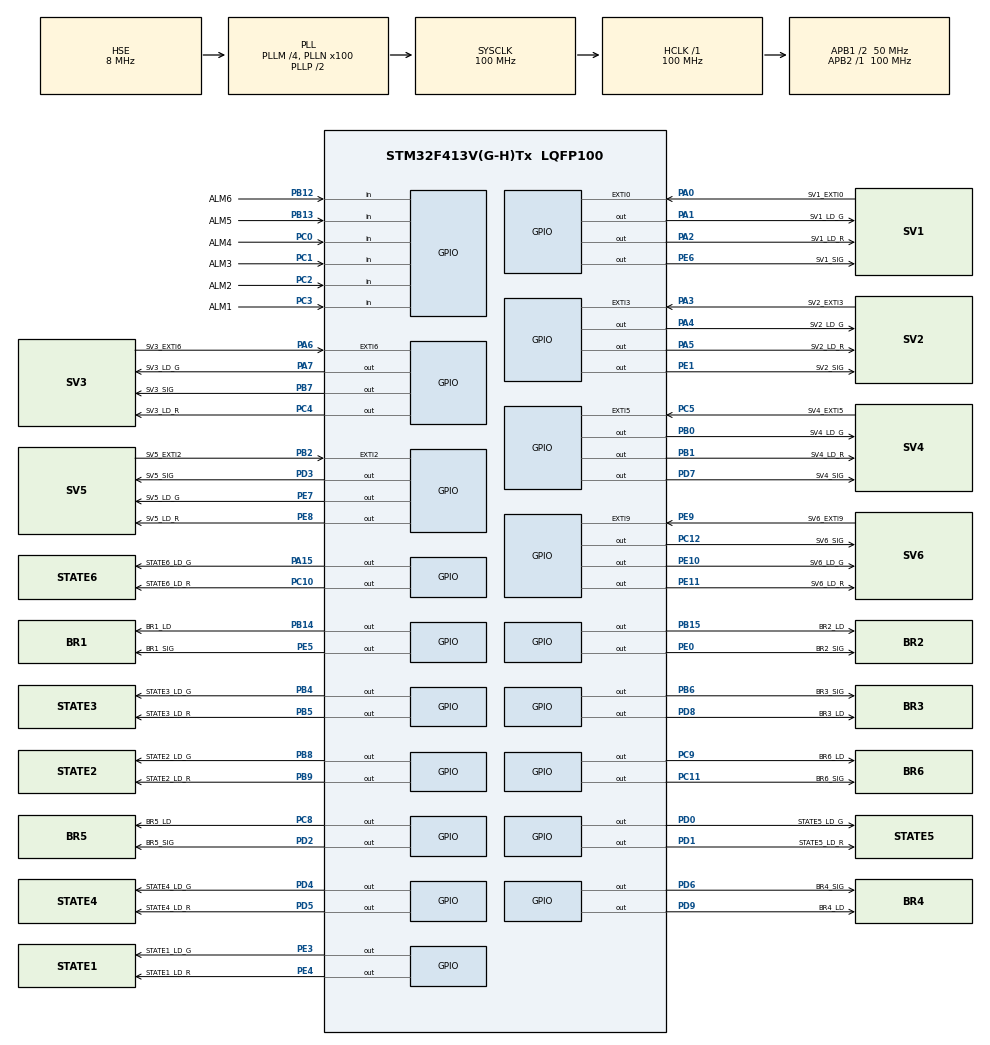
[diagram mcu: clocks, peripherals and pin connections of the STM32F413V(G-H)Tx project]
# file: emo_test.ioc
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Mcu.Family=STM32F4
Mcu.Name=STM32F413V(G-H)Tx
Mcu.Package=LQFP100
NVIC.EXTI0_IRQn=true\:0\:0\:false\:false\:true\:true\:true\:true
NVIC.EXTI2_IRQn=true\:0\:0\:false\:false\:true\:true\:true\:true
NVIC.EXTI3_IRQn=true\:0\:0\:false\:false\:true\:true\:true\:true
NVIC.EXTI9_5_IRQn=true\:0\:0\:false\:false\:true\:true\:true\:true
NVIC.PriorityGroup=NVIC_PRIORITYGROUP_4
NVIC.TIM2_IRQn=true\:0\:0\:false\:false\:true\:true\:true\:true
PA0.GPIO_Label=SV1_EXTI0
PA0.Signal=GPXTI0
PA1.GPIO_Label=SV1_LD_G
PA1.Signal=GPIO_Output
PA13.Mode=Trace_Asynchronous_SW
PA13.Signal=SYS_JTMS-SWDIO
PA14.Mode=Trace_Asynchronous_SW
PA14.Signal=SYS_JTCK-SWCLK
PA15.GPIO_Label=STATE6_LD_G
PA15.Signal=GPIO_Output
PA2.GPIO_Label=SV1_LD_R
PA2.Signal=GPIO_Output
PA3.GPIO_Label=SV2_EXTI3
PA3.Signal=GPXTI3
PA4.GPIO_Label=SV2_LD_G
PA4.Signal=GPIO_Output
PA5.GPIO_Label=SV2_LD_R
PA5.Signal=GPIO_Output
PA6.GPIO_Label=SV3_EXTI6
PA6.Signal=GPXTI6
PA7.GPIO_Label=SV3_LD_G
PA7.Signal=GPIO_Output
PB0.GPIO_Label=SV4_LD_G
PB0.Signal=GPIO_Output
PB1.GPIO_Label=SV4_LD_R
PB1.Signal=GPIO_Output
PB12.GPIO_Label=ALM6
PB12.Signal=GPIO_Input
PB13.GPIO_Label=ALM5
PB13.Signal=GPIO_Input
PB14.GPIO_Label=BR1_LD
PB14.Signal=GPIO_Output
PB15.GPIO_Label=BR2_LD
PB15.Signal=GPIO_Output
PB2.GPIO_Label=SV5_EXTI2
PB2.Signal=GPXTI2
PB3.Mode=Trace_Asynchronous_SW
PB3.Signal=SYS_JTDO-SWO
PB4.GPIO_Label=STATE3_LD_G
PB4.Signal=GPIO_Output
PB5.GPIO_Label=STATE3_LD_R
PB5.Signal=GPIO_Output
PB6.GPIO_Label=BR3_SIG
PB6.Signal=GPIO_Output
PB7.GPIO_Label=SV3_SIG
PB7.Signal=GPIO_Output
PB8.GPIO_Label=STATE2_LD_G
PB8.Signal=GPIO_Output
PB9.GPIO_Label=STATE2_LD_R
PB9.Signal=GPIO_Output
PC0.GPIO_Label=ALM4
PC0.Signal=GPIO_Input
PC1.GPIO_Label=ALM3
PC1.Signal=GPIO_Input
PC10.GPIO_Label=STATE6_LD_R
PC10.Signal=GPIO_Output
PC11.GPIO_Label=BR6_SIG
PC11.Signal=GPIO_Output
PC12.GPIO_Label=SV6_SIG
PC12.Signal=GPIO_Output
PC2.GPIO_Label=ALM2
PC2.Signal=GPIO_Input
PC3.GPIO_Label=ALM1
PC3.Signal=GPIO_Input
PC4.GPIO_Label=SV3_LD_R
PC4.Signal=GPIO_Output
PC5.GPIO_Label=SV4_EXTI5
PC5.Signal=GPXTI5
PC8.GPIO_Label=BR5_LD
PC8.Signal=GPIO_Output
PC9.GPIO_Label=BR6_LD
PC9.Signal=GPIO_Output
PD0.GPIO_Label=STATE5_LD_G
PD0.Signal=GPIO_Output
PD1.GPIO_Label=STATE5_LD_R
PD1.Signal=GPIO_Output
PD2.GPIO_Label=BR5_SIG
PD2.Signal=GPIO_Output
PD3.GPIO_Label=SV5_SIG
PD3.Signal=GPIO_Output
PD4.GPIO_Label=STATE4_LD_G
PD4.Signal=GPIO_Output
PD5.GPIO_Label=STATE4_LD_R
PD5.Signal=GPIO_Output
PD6.GPIO_Label=BR4_SIG
PD6.Signal=GPIO_Output
PD7.GPIO_Label=SV4_SIG
PD7.Signal=GPIO_Output
PD8.GPIO_Label=BR3_LD
PD8.Signal=GPIO_Output
PD9.GPIO_Label=BR4_LD
PD9.Signal=GPIO_Output
PE0.GPIO_Label=BR2_SIG
PE0.Signal=GPIO_Output
PE1.GPIO_Label=SV2_SIG
PE1.Signal=GPIO_Output
PE10.GPIO_Label=SV6_LD_G
PE10.Signal=GPIO_Output
PE11.GPIO_Label=SV6_LD_R
PE11.Signal=GPIO_Output
PE3.GPIO_Label=STATE1_LD_G
PE3.Signal=GPIO_Output
PE4.GPIO_Label=STATE1_LD_R
PE4.Signal=GPIO_Output
PE5.GPIO_Label=BR1_SIG
PE5.Signal=GPIO_Output
PE6.GPIO_Label=SV1_SIG
PE6.Signal=GPIO_Output
PE7.GPIO_Label=SV5_LD_G
PE7.Signal=GPIO_Output
PE8.GPIO_Label=SV5_LD_R
PE8.Signal=GPIO_Output
PE9.GPIO_Label=SV6_EXTI9
PE9.Signal=GPXTI9
PH0\ -\ OSC_IN.Mode=HSE-External-Clock-Source
PH0\ -\ OSC_IN.Signal=RCC_OSC_IN
PH1\ -\ OSC_OUT.Mode=HSE-External-Clock-Source
PH1\ -\ OSC_OUT.Signal=RCC_OSC_OUT
ProjectManager.HeapSize=0x200
ProjectManager.StackSize=0x400
ProjectManager.TargetToolchain=STM32CubeIDE
RCC.AHBFreq_Value=100000000
RCC.APB1CLKDivider=RCC_HCLK_DIV2
RCC.APB1Freq_Value=50000000
RCC.APB1TimFreq_Value=100000000
RCC.APB2Freq_Value=100000000
RCC.APB2TimFreq_Value=100000000
RCC.CortexFreq_Value=100000000
RCC.HCLKFreq_Value=100000000
RCC.HSE_VALUE=8000000
RCC.PLLM=4
RCC.PLLN=100
RCC.PLLSourceVirtual=RCC_PLLSOURCE_HSE
RCC.SYSCLKFreq_VALUE=100000000
RCC.SYSCLKSource=RCC_SYSCLKSOURCE_PLLCLK
RCC.USBFreq_Value=100000000
RCC.VCOOutputFreq_Value=200000000
TIM2.Period=100
TIM2.Prescaler=16-1
VP_TIM2_VS_ClockSourceINT.Mode=Internal
board=custom

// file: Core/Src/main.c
/* USER CODE BEGIN Header */
/**
  ******************************************************************************
  * @file           : main.c
  * @brief          : Main program body
  ******************************************************************************
  * @attention
  *
  * Copyright (c) 2024 STMicroelectronics.
  * All rights reserved.
  *
  * This software is licensed under terms that can be found in the LICENSE file
  * in the root directory of this software component.
  * If no LICENSE file comes with this software, it is provided AS-IS.
  *
  ******************************************************************************
  */
/* USER CODE END Header */
#include "main.h"

/* USER CODE BEGIN Includes */
#include "main_cpp.h"
/* USER CODE END Includes */

TIM_HandleTypeDef htim2;

void SystemClock_Config(void);
static void MX_GPIO_Init(void);
static void MX_TIM2_Init(void);

int main(void)
{

  /* MCU Configuration--------------------------------------------------------*/

  /* Reset of all peripherals, Initializes the Flash interface and the Systick. */
  HAL_Init();

  /* Configure the system clock */
  SystemClock_Config();

  /* Initialize all configured peripherals */
  MX_GPIO_Init();
  MX_TIM2_Init();
  /* USER CODE BEGIN 2 */

  main_cpp();
  /* USER CODE END 2 */

  /* Infinite loop */
  while (1)
  {

  }
}

void SystemClock_Config(void)
{
  RCC_OscInitTypeDef RCC_OscInitStruct = {0};
  RCC_ClkInitTypeDef RCC_ClkInitStruct = {0};

  /** Configure the main internal regulator output voltage
  */
  __HAL_RCC_PWR_CLK_ENABLE();
  __HAL_PWR_VOLTAGESCALING_CONFIG(PWR_REGULATOR_VOLTAGE_SCALE1);

  /** Initializes the RCC Oscillators according to the specified parameters
  * in the RCC_OscInitTypeDef structure.
  */
  RCC_OscInitStruct.OscillatorType = RCC_OSCILLATORTYPE_HSE;
  RCC_OscInitStruct.HSEState = RCC_HSE_BYPASS;
  RCC_OscInitStruct.PLL.PLLState = RCC_PLL_ON;
  RCC_OscInitStruct.PLL.PLLSource = RCC_PLLSOURCE_HSE;
  RCC_OscInitStruct.PLL.PLLM = 4;
  RCC_OscInitStruct.PLL.PLLN = 100;
  RCC_OscInitStruct.PLL.PLLP = RCC_PLLP_DIV2;
  RCC_OscInitStruct.PLL.PLLQ = 2;
  RCC_OscInitStruct.PLL.PLLR = 2;
  if (HAL_RCC_OscConfig(&RCC_OscInitStruct) != HAL_OK)
  {
    Error_Handler();
  }

  /** Initializes the CPU, AHB and APB buses clocks
  */
  RCC_ClkInitStruct.ClockType = RCC_CLOCKTYPE_HCLK|RCC_CLOCKTYPE_SYSCLK
                              |RCC_CLOCKTYPE_PCLK1|RCC_CLOCKTYPE_PCLK2;
  RCC_ClkInitStruct.SYSCLKSource = RCC_SYSCLKSOURCE_PLLCLK;
  RCC_ClkInitStruct.AHBCLKDivider = RCC_SYSCLK_DIV1;
  RCC_ClkInitStruct.APB1CLKDivider = RCC_HCLK_DIV2;
  RCC_ClkInitStruct.APB2CLKDivider = RCC_HCLK_DIV1;

  if (HAL_RCC_ClockConfig(&RCC_ClkInitStruct, FLASH_LATENCY_3) != HAL_OK)
  {
    Error_Handler();
  }
}

static void MX_TIM2_Init(void)
{

  TIM_ClockConfigTypeDef sClockSourceConfig = {0};
  TIM_MasterConfigTypeDef sMasterConfig = {0};

  htim2.Instance = TIM2;
  htim2.Init.Prescaler = 16-1;
  htim2.Init.CounterMode = TIM_COUNTERMODE_UP;
  htim2.Init.Period = 100;
  htim2.Init.ClockDivision = TIM_CLOCKDIVISION_DIV1;
  htim2.Init.AutoReloadPreload = TIM_AUTORELOAD_PRELOAD_DISABLE;
  if (HAL_TIM_Base_Init(&htim2) != HAL_OK)
  {
    Error_Handler();
  }
  sClockSourceConfig.ClockSource = TIM_CLOCKSOURCE_INTERNAL;
  if (HAL_TIM_ConfigClockSource(&htim2, &sClockSourceConfig) != HAL_OK)
  {
    Error_Handler();
  }
  sMasterConfig.MasterOutputTrigger = TIM_TRGO_RESET;
  sMasterConfig.MasterSlaveMode = TIM_MASTERSLAVEMODE_DISABLE;
  if (HAL_TIMEx_MasterConfigSynchronization(&htim2, &sMasterConfig) != HAL_OK)
  {
    Error_Handler();
  }

}

static void MX_GPIO_Init(void)
{
  GPIO_InitTypeDef GPIO_InitStruct = {0};

  /* GPIO Ports Clock Enable */
  __HAL_RCC_GPIOE_CLK_ENABLE();
  __HAL_RCC_GPIOH_CLK_ENABLE();
  __HAL_RCC_GPIOC_CLK_ENABLE();
  __HAL_RCC_GPIOA_CLK_ENABLE();
  __HAL_RCC_GPIOB_CLK_ENABLE();
  __HAL_RCC_GPIOD_CLK_ENABLE();

  /*Configure GPIO pin Output Level */
  HAL_GPIO_WritePin(GPIOE, STATE1_LD_G_Pin|STATE1_LD_R_Pin|BR1_SIG_Pin|SV1_SIG_Pin
                          |SV5_LD_G_Pin|SV5_LD_R_Pin|SV6_LD_G_Pin|SV6_LD_R_Pin
                          |BR2_SIG_Pin|SV2_SIG_Pin, GPIO_PIN_RESET);

  /*Configure GPIO pin Output Level */
  HAL_GPIO_WritePin(GPIOA, SV1_LD_G_Pin|SV1_LD_R_Pin|SV2_LD_G_Pin|SV2_LD_R_Pin
                          |SV3_LD_G_Pin|STATE6_LD_G_Pin, GPIO_PIN_RESET);

  /*Configure GPIO pin Output Level */
  HAL_GPIO_WritePin(GPIOC, SV3_LD_R_Pin|BR5_LD_Pin|BR6_LD_Pin|STATE6_LD_R_Pin
                          |BR6_SIG_Pin|SV6_SIG_Pin, GPIO_PIN_RESET);

  /*Configure GPIO pin Output Level */
  HAL_GPIO_WritePin(GPIOB, SV4_LD_G_Pin|SV4_LD_R_Pin|BR1_LD_Pin|BR2_LD_Pin
                          |STATE3_LD_G_Pin|STATE3_LD_R_Pin|BR3_SIG_Pin|SV3_SIG_Pin
                          |STATE2_LD_G_Pin|STATE2_LD_R_Pin, GPIO_PIN_RESET);

  /*Configure GPIO pin Output Level */
  HAL_GPIO_WritePin(GPIOD, BR3_LD_Pin|BR4_LD_Pin|STATE5_LD_G_Pin|STATE5_LD_R_Pin
                          |BR5_SIG_Pin|SV5_SIG_Pin|STATE4_LD_G_Pin|STATE4_LD_R_Pin
                          |BR4_SIG_Pin|SV4_SIG_Pin, GPIO_PIN_RESET);

  /*Configure GPIO pins : STATE1_LD_G_Pin STATE1_LD_R_Pin BR1_SIG_Pin SV1_SIG_Pin
                           SV5_LD_G_Pin SV5_LD_R_Pin SV6_LD_G_Pin SV6_LD_R_Pin
                           BR2_SIG_Pin SV2_SIG_Pin */
  GPIO_InitStruct.Pin = STATE1_LD_G_Pin|STATE1_LD_R_Pin|BR1_SIG_Pin|SV1_SIG_Pin
                          |SV5_LD_G_Pin|SV5_LD_R_Pin|SV6_LD_G_Pin|SV6_LD_R_Pin
                          |BR2_SIG_Pin|SV2_SIG_Pin;
  GPIO_InitStruct.Mode = GPIO_MODE_OUTPUT_PP;
  GPIO_InitStruct.Pull = GPIO_NOPULL;
  GPIO_InitStruct.Speed = GPIO_SPEED_FREQ_LOW;
  HAL_GPIO_Init(GPIOE, &GPIO_InitStruct);

  /*Configure GPIO pins : ALM4_Pin ALM3_Pin ALM2_Pin ALM1_Pin */
  GPIO_InitStruct.Pin = ALM4_Pin|ALM3_Pin|ALM2_Pin|ALM1_Pin;
  GPIO_InitStruct.Mode = GPIO_MODE_INPUT;
  GPIO_InitStruct.Pull = GPIO_NOPULL;
  HAL_GPIO_Init(GPIOC, &GPIO_InitStruct);

  /*Configure GPIO pins : SV1_EXTI0_Pin SV2_EXTI3_Pin SV3_EXTI6_Pin */
  GPIO_InitStruct.Pin = SV1_EXTI0_Pin|SV2_EXTI3_Pin|SV3_EXTI6_Pin;
  GPIO_InitStruct.Mode = GPIO_MODE_IT_RISING;
  GPIO_InitStruct.Pull = GPIO_NOPULL;
  HAL_GPIO_Init(GPIOA, &GPIO_InitStruct);

  /*Configure GPIO pins : SV1_LD_G_Pin SV1_LD_R_Pin SV2_LD_G_Pin SV2_LD_R_Pin
                           SV3_LD_G_Pin STATE6_LD_G_Pin */
  GPIO_InitStruct.Pin = SV1_LD_G_Pin|SV1_LD_R_Pin|SV2_LD_G_Pin|SV2_LD_R_Pin
                          |SV3_LD_G_Pin|STATE6_LD_G_Pin;
  GPIO_InitStruct.Mode = GPIO_MODE_OUTPUT_PP;
  GPIO_InitStruct.Pull = GPIO_NOPULL;
  GPIO_InitStruct.Speed = GPIO_SPEED_FREQ_LOW;
  HAL_GPIO_Init(GPIOA, &GPIO_InitStruct);

  /*Configure GPIO pins : SV3_LD_R_Pin BR5_LD_Pin BR6_LD_Pin STATE6_LD_R_Pin
                           BR6_SIG_Pin SV6_SIG_Pin */
  GPIO_InitStruct.Pin = SV3_LD_R_Pin|BR5_LD_Pin|BR6_LD_Pin|STATE6_LD_R_Pin
                          |BR6_SIG_Pin|SV6_SIG_Pin;
  GPIO_InitStruct.Mode = GPIO_MODE_OUTPUT_PP;
  GPIO_InitStruct.Pull = GPIO_NOPULL;
  GPIO_InitStruct.Speed = GPIO_SPEED_FREQ_LOW;
  HAL_GPIO_Init(GPIOC, &GPIO_InitStruct);

  /*Configure GPIO pin : SV4_EXTI5_Pin */
  GPIO_InitStruct.Pin = SV4_EXTI5_Pin;
  GPIO_InitStruct.Mode = GPIO_MODE_IT_RISING;
  GPIO_InitStruct.Pull = GPIO_NOPULL;
  HAL_GPIO_Init(SV4_EXTI5_GPIO_Port, &GPIO_InitStruct);

  /*Configure GPIO pins : SV4_LD_G_Pin SV4_LD_R_Pin BR1_LD_Pin BR2_LD_Pin
                           STATE3_LD_G_Pin STATE3_LD_R_Pin BR3_SIG_Pin SV3_SIG_Pin
                           STATE2_LD_G_Pin STATE2_LD_R_Pin */
  GPIO_InitStruct.Pin = SV4_LD_G_Pin|SV4_LD_R_Pin|BR1_LD_Pin|BR2_LD_Pin
                          |STATE3_LD_G_Pin|STATE3_LD_R_Pin|BR3_SIG_Pin|SV3_SIG_Pin
                          |STATE2_LD_G_Pin|STATE2_LD_R_Pin;
  GPIO_InitStruct.Mode = GPIO_MODE_OUTPUT_PP;
  GPIO_InitStruct.Pull = GPIO_NOPULL;
  GPIO_InitStruct.Speed = GPIO_SPEED_FREQ_LOW;
  HAL_GPIO_Init(GPIOB, &GPIO_InitStruct);

  /*Configure GPIO pin : SV5_EXTI2_Pin */
  GPIO_InitStruct.Pin = SV5_EXTI2_Pin;
  GPIO_InitStruct.Mode = GPIO_MODE_IT_RISING;
  GPIO_InitStruct.Pull = GPIO_NOPULL;
  HAL_GPIO_Init(SV5_EXTI2_GPIO_Port, &GPIO_InitStruct);

  /*Configure GPIO pin : SV6_EXTI9_Pin */
  GPIO_InitStruct.Pin = SV6_EXTI9_Pin;
  GPIO_InitStruct.Mode = GPIO_MODE_IT_RISING;
  GPIO_InitStruct.Pull = GPIO_NOPULL;
  HAL_GPIO_Init(SV6_EXTI9_GPIO_Port, &GPIO_InitStruct);

  /*Configure GPIO pins : ALM6_Pin ALM5_Pin */
  GPIO_InitStruct.Pin = ALM6_Pin|ALM5_Pin;
  GPIO_InitStruct.Mode = GPIO_MODE_INPUT;
  GPIO_InitStruct.Pull = GPIO_NOPULL;
  HAL_GPIO_Init(GPIOB, &GPIO_InitStruct);

  /*Configure GPIO pins : BR3_LD_Pin BR4_LD_Pin STATE5_LD_G_Pin STATE5_LD_R_Pin
                           BR5_SIG_Pin SV5_SIG_Pin STATE4_LD_G_Pin STATE4_LD_R_Pin
                           BR4_SIG_Pin SV4_SIG_Pin */
  GPIO_InitStruct.Pin = BR3_LD_Pin|BR4_LD_Pin|STATE5_LD_G_Pin|STATE5_LD_R_Pin
                          |BR5_SIG_Pin|SV5_SIG_Pin|STATE4_LD_G_Pin|STATE4_LD_R_Pin
                          |BR4_SIG_Pin|SV4_SIG_Pin;
  GPIO_InitStruct.Mode = GPIO_MODE_OUTPUT_PP;
  GPIO_InitStruct.Pull = GPIO_NOPULL;
  GPIO_InitStruct.Speed = GPIO_SPEED_FREQ_LOW;
  HAL_GPIO_Init(GPIOD, &GPIO_InitStruct);

  /* EXTI interrupt init*/
  HAL_NVIC_SetPriority(EXTI0_IRQn, 0, 0);
  HAL_NVIC_EnableIRQ(EXTI0_IRQn);

  HAL_NVIC_SetPriority(EXTI2_IRQn, 0, 0);
  HAL_NVIC_EnableIRQ(EXTI2_IRQn);

  HAL_NVIC_SetPriority(EXTI3_IRQn, 0, 0);
  HAL_NVIC_EnableIRQ(EXTI3_IRQn);

  HAL_NVIC_SetPriority(EXTI9_5_IRQn, 0, 0);
  HAL_NVIC_EnableIRQ(EXTI9_5_IRQn);

}

void Error_Handler(void)
{
  __disable_irq();
  while (1)
  {
  }
}
